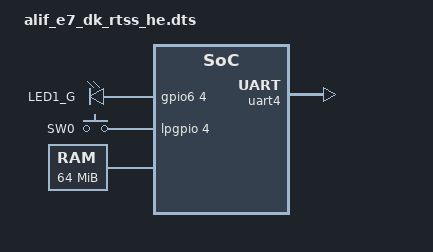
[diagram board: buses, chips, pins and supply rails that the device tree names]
/* Copyright (c) 2024 Alif Semiconductor
 *
 * SPDX-License-Identifier: Apache-2.0
 */
/dts-v1/;

#include <alif/e7_rtss_common.dtsi>
#include <alif/ensemble_rtss_he.dtsi>
#include <alif/ensemble-pinctrl.dtsi>

/ {
	compatible = "arm,alif-e7-dk-rtss-he";
	#address-cells = <1>;
	#size-cells = <1>;

	chosen {
		zephyr,flash = &mram_storage;
		zephyr,code-partition = &slot0_partition;
		zephyr,sram = &dtcm;
		zephyr,console = &uart4;
		zephyr,shell-uart = &uart4;
		zephyr,uart-mcumgr = &uart4;
	};

	aliases {
		led0 = &aled0;
		sw0 = &button0;
	};
	leds {
		compatible = "gpio-leds";
		aled0: led_0 {
			gpios = <&gpio6 4 0>;
			label = "LED1_G";
		};
	};
	buttons {
		compatible = "gpio-keys";
		button0: button_0 {
			gpios = < &lpgpio 4 0 >;
			label = "SW0";
		};
	};
	ext_flash_xip: memory@c0000000 {
		compatible = "zephyr,memory-region";
		reg = <0xc0000000 DT_SIZE_M(64)>;
		zephyr,memory-region = "OSPI1";
	};
};

&uart4 {
	status = "okay";
};
